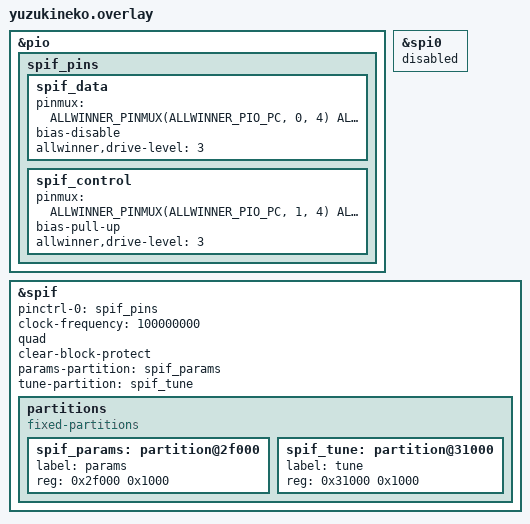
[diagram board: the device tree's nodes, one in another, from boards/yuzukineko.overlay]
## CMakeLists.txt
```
# Copyright (c) 2026 Yuzuki Tsuru
# SPDX-License-Identifier: Apache-2.0

cmake_minimum_required(VERSION 3.20.0)
find_package(Zephyr REQUIRED HINTS $ENV{ZEPHYR_BASE})
project(uf2_downloader)

target_sources(app PRIVATE src/main.c src/uf2.c src/msc.c)

# the flash is written from the MSC thread, not from the interrupt; one 4 KiB transfer at a time
zephyr_compile_definitions(CONFIG_USBDEV_MSC_THREAD=1 CONFIG_USBDEV_MSC_STACKSIZE=4096)
```

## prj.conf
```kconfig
CONFIG_CHERRYUSB=y
CONFIG_CHERRYUSB_DEVICE=y
CONFIG_CHERRYUSB_DEVICE_SPEED_HS=y
CONFIG_CHERRYUSB_DEVICE_MUSB_SUNXI=y
CONFIG_CHERRYUSB_DEVICE_MSC=y

CONFIG_FLASH=y
CONFIG_FLASH_PAGE_LAYOUT=y
CONFIG_CRC=y
CONFIG_ICACHE=y

CONFIG_PRINTK=y
CONFIG_LOG=n
CONFIG_SHELL=n
CONFIG_DEVMEM_SHELL=n
CONFIG_MAIN_STACK_SIZE=8192
CONFIG_SYSTEM_WORKQUEUE_STACK_SIZE=2048
CONFIG_HEAP_MEM_POOL_SIZE=65536

# nothing of the board is needed but the flash and the USB port
CONFIG_DISPLAY=n
CONFIG_G2D=n
CONFIG_VDEC=n
CONFIG_ADC=n
CONFIG_SPI=n
CONFIG_I2C=n
CONFIG_MIPI_DBI=n
CONFIG_WDT_SUNXI=n
CONFIG_REBOOT=y
CONFIG_USBDEV_MSC_MAX_BUFSIZE=4096
```

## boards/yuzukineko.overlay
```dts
/*
 * The SPI NOR flash (16 MiB) is on PC0..PC5, the pins of spi0.
 *
 *   0x000000  three copies of the boot loader (160 KiB)
 *   0x02f000  saved sample point of the flash controller
 *   0x030000  this program: header page, then the image (tune data = its first words)
 *   0x200000  applications (header page, then the image)
 */

#include <zephyr/dt-bindings/pinctrl/allwinner-pinctrl.h>

&pio {
	spif_pins: spif_pins {
		spif_data {
			pinmux = <ALLWINNER_PINMUX(ALLWINNER_PIO_PC, 0, 4)
				  ALLWINNER_PINMUX(ALLWINNER_PIO_PC, 4, 4)
				  ALLWINNER_PINMUX(ALLWINNER_PIO_PC, 2, 4)>;
			bias-disable;
			allwinner,drive-level = <3>;
		};
		spif_control {
			pinmux = <ALLWINNER_PINMUX(ALLWINNER_PIO_PC, 1, 4)
				  ALLWINNER_PINMUX(ALLWINNER_PIO_PC, 3, 4)
				  ALLWINNER_PINMUX(ALLWINNER_PIO_PC, 5, 4)>;
			bias-pull-up;
			allwinner,drive-level = <3>;
		};
	};
};

&spi0 {
	status = "disabled";
};

&spif {
	status = "okay";
	pinctrl-0 = <&spif_pins>;
	pinctrl-names = "default";
	clock-frequency = <100000000>;
	quad;
	clear-block-protect;
	params-partition = "spif_params";
	tune-partition = "spif_tune";

	partitions {
		compatible = "fixed-partitions";
		#address-cells = <1>;
		#size-cells = <1>;

		spif_params: partition@2f000 {
			label = "params";
			reg = <0x2f000 0x1000>;
		};
		spif_tune: partition@31000 {
			label = "tune";
			reg = <0x31000 0x1000>;
		};
	};
};
```

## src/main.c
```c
/*
 * Copyright (c) 2026 Yuzuki Tsuru
 * SPDX-License-Identifier: Apache-2.0
 */

/*
 * UF2 boot mode: the board shows up as a USB drive, a .uf2 file copied onto it is written
 * to the SPI NOR flash, and the board restarts into the application when the file is done.
 * The boot loader starts this program when the key is held or no application is in the flash.
 */

#include <zephyr/device.h>
#include <zephyr/drivers/gpio.h>
#include <zephyr/kernel.h>
#include <zephyr/sys/printk.h>
#include <zephyr/sys/reboot.h>

#include "usbd_core.h"
#include "usbd_msc.h"

#include "uf2.h"

extern uintptr_t usb_sunxi_otg_base(void);

#define MSC_IN_EP  0x81
#define MSC_OUT_EP 0x02

#define USBD_VID	   0x1209
#define USBD_PID	   0xF101
#define USBD_MAX_POWER	   100
#define USB_CONFIG_SIZE	   (9 + MSC_DESCRIPTOR_LEN)

static const uint8_t device_descriptor[] = {
	USB_DEVICE_DESCRIPTOR_INIT(USB_2_0, 0x00, 0x00, 0x00, USBD_VID, USBD_PID, 0x0200, 0x01)
};

static const uint8_t config_hs[] = {
	USB_CONFIG_DESCRIPTOR_INIT(USB_CONFIG_SIZE, 0x01, 0x01, USB_CONFIG_BUS_POWERED,
				   USBD_MAX_POWER),
	MSC_DESCRIPTOR_INIT(0x00, MSC_OUT_EP, MSC_IN_EP, USB_BULK_EP_MPS_HS, 0x02)
};

static const uint8_t config_fs[] = {
	USB_CONFIG_DESCRIPTOR_INIT(USB_CONFIG_SIZE, 0x01, 0x01, USB_CONFIG_BUS_POWERED,
				   USBD_MAX_POWER),
	MSC_DESCRIPTOR_INIT(0x00, MSC_OUT_EP, MSC_IN_EP, USB_BULK_EP_MPS_FS, 0x02)
};

static const uint8_t qualifier[] = {USB_DEVICE_QUALIFIER_DESCRIPTOR_INIT(USB_2_0, 0x00, 0x00, 0x00, 0x01)};

static const uint8_t other_hs[] = {
	USB_OTHER_SPEED_CONFIG_DESCRIPTOR_INIT(USB_CONFIG_SIZE, 0x01, 0x01, USB_CONFIG_BUS_POWERED,
					       USBD_MAX_POWER),
	MSC_DESCRIPTOR_INIT(0x00, MSC_OUT_EP, MSC_IN_EP, USB_BULK_EP_MPS_FS, 0x02)
};

static const uint8_t other_fs[] = {
	USB_OTHER_SPEED_CONFIG_DESCRIPTOR_INIT(USB_CONFIG_SIZE, 0x01, 0x01, USB_CONFIG_BUS_POWERED,
					       USBD_MAX_POWER),
	MSC_DESCRIPTOR_INIT(0x00, MSC_OUT_EP, MSC_IN_EP, USB_BULK_EP_MPS_HS, 0x02)
};

static const char *strings[] = {
	(const char[]){0x09, 0x04},
	"Yuzuki",
	"F101 UF2 Bootloader",
	"F101BOOT0001",
};

static const uint8_t *device_cb(uint8_t speed)
{
	return device_descriptor;
}

static const uint8_t *config_cb(uint8_t speed)
{
	return speed == USB_SPEED_HIGH ? config_hs : speed == USB_SPEED_FULL ? config_fs : NULL;
}

static const uint8_t *qualifier_cb(uint8_t speed)
{
	return qualifier;
}

static const uint8_t *other_cb(uint8_t speed)
{
	return speed == USB_SPEED_HIGH ? other_hs : speed == USB_SPEED_FULL ? other_fs : NULL;
}

static const char *string_cb(uint8_t speed, uint8_t index)
{
	return index < ARRAY_SIZE(strings) ? strings[index] : NULL;
}

static const struct usb_descriptor descriptor = {
	.device_descriptor_callback = device_cb,
	.config_descriptor_callback = config_cb,
	.device_quality_descriptor_callback = qualifier_cb,
	.other_speed_descriptor_callback = other_cb,
	.string_descriptor_callback = string_cb,
};

static struct usbd_interface intf0;

static void event_handler(uint8_t busid, uint8_t event)
{
	if (event == USBD_EVENT_CONFIGURED) {
		printk("uf2-downloader: USB configured\n");
	}
}

int main(void)
{
	int ret = uf2_init();

	if (ret != 0) {
		printk("[E] uf2-downloader: flash not usable: %d\n", ret);
		return 0;
	}
	usbd_desc_register(0, &descriptor);
	usbd_add_interface(0, usbd_msc_init_intf(0, &intf0, MSC_OUT_EP, MSC_IN_EP));
	usbd_initialize(0, usb_sunxi_otg_base(), event_handler);
	printk("uf2-downloader: ready, copy a .uf2 file onto the F101BOOT drive\n");

	uint32_t last = 0;
	int quiet = 0, key = -1;
	const struct device *gpio = DEVICE_DT_GET(DT_NODELABEL(gpiod));

	gpio_pin_configure(gpio, 5, GPIO_INPUT | GPIO_PULL_UP);

	while (true) {
		k_msleep(20);
		int level = gpio_pin_get_raw(gpio, 5);

		if (level != key) {
			key = level;
			printk("uf2-downloader: key (PD5) = %d\n", key);
		}
		if (uf2_complete()) {
			/* the host still writes its file system tables */
			k_msleep(1000);
			printk("uf2-downloader: done, restarting\n");
			sys_reboot(SYS_REBOOT_COLD);
		}
		if (uf2_blocks_done() != last) {
			last = uf2_blocks_done();
			quiet = 0;
		} else if (++quiet == 250 && last != 0U) {
			printk("uf2-downloader: %u of %u blocks, %u errors\n", last, uf2_blocks_total(),
			       uf2_errors());
		}
	}
	return 0;
}
```

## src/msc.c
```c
/*
 * Copyright (c) 2026 Yuzuki Tsuru
 * SPDX-License-Identifier: Apache-2.0
 */

/*
 * A FAT16 volume that exists only as the code below: the boot sector, the tables, the root
 * directory and two small files are made when read, everything written is looked at for
 * UF2 blocks and dropped otherwise. 128 MiB, so a big UF2 file is not refused for space.
 */

#include <string.h>

#include "usbd_core.h"
#include "usbd_msc.h"

#include "uf2.h"

#define SECTOR_SIZE	512U
#define NUM_SECTORS	262144U
#define SEC_PER_CLUSTER 8U
#define FAT_SECTORS	128U /* 32768 clusters * 2 bytes */
#define ROOT_ENTRIES	512U
#define ROOT_SECTORS	(ROOT_ENTRIES * 32U / SECTOR_SIZE)
#define FAT1_START	1U
#define FAT2_START	(FAT1_START + FAT_SECTORS)
#define ROOT_START	(FAT2_START + FAT_SECTORS)
#define DATA_START	(ROOT_START + ROOT_SECTORS)

static const char info_txt[] =
	"UF2 Bootloader for the Allwinner F101\r\n"
	"Model: YuzukiNeko\r\n"
	"Board-ID: F101-Neko\r\n"
	"Flash: applications from 0x200000, family 0x31303146\r\n";

static const char index_htm[] =
	"<!doctype html><html><body><script>location.replace(\"https://github.com/YuzukiHD\");"
	"</script></body></html>\r\n";

struct vfile {
	const char name[11];
	const char *data;
	uint16_t size;
};

static const struct vfile files[] = {
	{"INFO_UF2TXT", info_txt, sizeof(info_txt) - 1},
	{"INDEX   HTM", index_htm, sizeof(index_htm) - 1},
};

#define FIRST_FILE_CLUSTER 2U

static void put16(uint8_t *p, uint16_t v)
{
	p[0] = v;
	p[1] = v >> 8;
}

static void put32(uint8_t *p, uint32_t v)
{
	put16(p, v);
	put16(p + 2, v >> 16);
}

static void boot_sector(uint8_t *b)
{
	memset(b, 0, SECTOR_SIZE);
	b[0] = 0xEB;
	b[1] = 0x3C;
	b[2] = 0x90;
	memcpy(b + 3, "UF2 UF2 ", 8);
	put16(b + 11, SECTOR_SIZE);
	b[13] = SEC_PER_CLUSTER;
	put16(b + 14, 1);
	b[16] = 2;
	put16(b + 17, ROOT_ENTRIES);
	put16(b + 19, 0);
	b[21] = 0xF8;
	put16(b + 22, FAT_SECTORS);
	put16(b + 24, 63);
	put16(b + 26, 255);
	put32(b + 28, 0);
	put32(b + 32, NUM_SECTORS);
	b[36] = 0x80;
	b[38] = 0x29;
	put32(b + 39, 0x00420042);
	memcpy(b + 43, "F101BOOT   ", 11);
	memcpy(b + 54, "FAT16   ", 8);
	b[510] = 0x55;
	b[511] = 0xAA;
}

static uint16_t fat_entry(uint32_t idx)
{
	if (idx == 0) {
		return 0xFFF8;
	}
	if (idx == 1) {
		return 0xFFFF;
	}
	if (idx >= FIRST_FILE_CLUSTER && idx < FIRST_FILE_CLUSTER + ARRAY_SIZE(files)) {
		return 0xFFFF; /* every file is one cluster */
	}
	return 0;
}

static void root_sector(uint32_t n, uint8_t *b)
{
	memset(b, 0, SECTOR_SIZE);
	if (n != 0U) {
		return;
	}
	/* volume label, then the files; 1 Jan 2026 */
	memcpy(b, "F101BOOT   ", 11);
	b[11] = 0x08;
	for (unsigned int i = 0; i < ARRAY_SIZE(files); i++) {
		uint8_t *e = b + 32 * (i + 1);

		memcpy(e, files[i].name, 11);
		e[11] = 0x01; /* read only */
		put16(e + 14, 0);
		put16(e + 16, ((2026 - 1980) << 9) | (1 << 5) | 1);
		put16(e + 24, ((2026 - 1980) << 9) | (1 << 5) | 1);
		put16(e + 26, FIRST_FILE_CLUSTER + i);
		put32(e + 28, files[i].size);
	}
}

static void read_sector(uint32_t s, uint8_t *b)
{
	if (s == 0U) {
		boot_sector(b);
	} else if (s < ROOT_START) {
		uint32_t n = (s - FAT1_START) % FAT_SECTORS;

		for (unsigned int i = 0; i < SECTOR_SIZE / 2U; i++) {
			put16(b + 2U * i, fat_entry(n * (SECTOR_SIZE / 2U) + i));
		}
	} else if (s < DATA_START) {
		root_sector(s - ROOT_START, b);
	} else {
		uint32_t cluster = FIRST_FILE_CLUSTER + (s - DATA_START) / SEC_PER_CLUSTER;
		uint32_t in_cluster = (s - DATA_START) % SEC_PER_CLUSTER;

		memset(b, 0, SECTOR_SIZE);
		if (cluster < FIRST_FILE_CLUSTER + ARRAY_SIZE(files) && in_cluster == 0U) {
			const struct vfile *f = &files[cluster - FIRST_FILE_CLUSTER];

			memcpy(b, f->data, f->size);
		}
	}
}

void usbd_msc_get_cap(uint8_t busid, uint8_t lun, uint32_t *block_num, uint32_t *block_size)
{
	*block_num = NUM_SECTORS;
	*block_size = SECTOR_SIZE;
}

int usbd_msc_sector_read(uint8_t busid, uint8_t lun, uint32_t sector, uint8_t *buffer,
			 uint32_t length)
{
	for (uint32_t i = 0; i < length / SECTOR_SIZE; i++) {
		read_sector(sector + i, buffer + i * SECTOR_SIZE);
	}
	return 0;
}

int usbd_msc_sector_write(uint8_t busid, uint8_t lun, uint32_t sector, uint8_t *buffer,
			  uint32_t length)
{
	for (uint32_t i = 0; i < length / SECTOR_SIZE; i++) {
		(void)uf2_write_block(buffer + i * SECTOR_SIZE);
	}
	return 0;
}
```

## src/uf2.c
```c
/*
 * Copyright (c) 2026 Yuzuki Tsuru
 * SPDX-License-Identifier: Apache-2.0
 */

/* UF2 blocks -> SPI NOR flash */

#include <string.h>

#include <zephyr/device.h>
#include <zephyr/drivers/flash.h>
#include <zephyr/kernel.h>
#include <zephyr/sys/printk.h>

#include "uf2.h"

#define SECTOR 4096U

static const struct device *const flash = DEVICE_DT_GET(DT_NODELABEL(spif));
static uint32_t flash_size;
/* 4 KiB sectors erased for the file in progress */
static uint8_t erased[4096 / 8];
static uint32_t done, total, errors;
static bool complete;
static uint32_t file_family;

int uf2_init(void)
{
	uint64_t size;

	if (!device_is_ready(flash)) {
		return -ENODEV;
	}
	if (flash_get_size(flash, &size) != 0 || size == 0U) {
		return -EIO;
	}
	flash_size = size;
	return 0;
}

static bool allowed(uint32_t family, uint32_t addr, uint32_t len)
{
	if (len == 0U || addr + len < addr || addr + len > flash_size) {
		return false;
	}
	if (family == UF2_FAMILY_APP) {
		return addr >= UF2_APP_BASE;
	}
	return family == UF2_FAMILY_SYS;
}

static int prepare(uint32_t addr, uint32_t len)
{
	for (uint32_t s = addr / SECTOR; s <= (addr + len - 1U) / SECTOR; s++) {
		if (erased[s / 8U] & BIT(s % 8U)) {
			continue;
		}
		int ret = flash_erase(flash, s * SECTOR, SECTOR);

		if (ret != 0) {
			return ret;
		}
		erased[s / 8U] |= BIT(s % 8U);
	}
	return 0;
}

bool uf2_write_block(const uint8_t *buf)
{
	const struct uf2_block *b = (const struct uf2_block *)buf;

	if (b->magic0 != UF2_MAGIC_START0 || b->magic1 != UF2_MAGIC_START1 ||
	    b->magic_end != UF2_MAGIC_END) {
		return false;
	}
	if ((b->flags & UF2_FLAG_NOT_MAIN_FLASH) != 0U) {
		return true;
	}
	if ((b->flags & UF2_FLAG_FAMILY_ID) == 0U || b->payload_size > sizeof(b->data) ||
	    !allowed(b->family, b->target_addr, b->payload_size)) {
		errors++;
		printk("uf2: block %u refused (family 0x%08x, address 0x%08x, %u bytes)\n",
		       b->block_no, b->family, b->target_addr, b->payload_size);
		return true;
	}
	if (b->block_no == 0U || b->family != file_family || b->num_blocks != total) {
		/* the first block of a new file */
		memset(erased, 0, sizeof(erased));
		done = 0;
		errors = 0;
		complete = false;
		total = b->num_blocks;
		file_family = b->family;
		printk("uf2: new file, %u blocks, family 0x%08x\n", total, file_family);
	}
	if (prepare(b->target_addr, b->payload_size) != 0 ||
	    flash_write(flash, b->target_addr, b->data, b->payload_size) != 0) {
		errors++;
		printk("uf2: flash error at 0x%08x\n", b->target_addr);
		return true;
	}
	if (++done >= total && errors == 0U) {
		complete = true;
		printk("uf2: %u blocks written\n", done);
	}
	return true;
}

uint32_t uf2_blocks_done(void)
{
	return done;
}

uint32_t uf2_blocks_total(void)
{
	return total;
}

uint32_t uf2_errors(void)
{
	return errors;
}

bool uf2_complete(void)
{
	return complete;
}
```

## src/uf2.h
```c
/* SPDX-License-Identifier: Apache-2.0 */
#pragma once

#include <stdbool.h>
#include <stdint.h>

#define UF2_MAGIC_START0 0x0A324655U /* "UF2\n" */
#define UF2_MAGIC_START1 0x9E5D5157U
#define UF2_MAGIC_END	 0x0AB16F30U

#define UF2_FLAG_NOT_MAIN_FLASH 0x00000001U
#define UF2_FLAG_FAMILY_ID	0x00002000U

/* applications: flash offsets from APP_BASE on */
#define UF2_FAMILY_APP 0x31303146U
/* everything (loader, this program): the same file format, offsets from 0 */
#define UF2_FAMILY_SYS 0x31303147U

#define UF2_APP_BASE 0x00200000U

struct uf2_block {
	uint32_t magic0, magic1;
	uint32_t flags;
	uint32_t target_addr;
	uint32_t payload_size;
	uint32_t block_no;
	uint32_t num_blocks;
	uint32_t family;
	uint8_t data[476];
	uint32_t magic_end;
};

/** Initialise; returns 0 or a negative errno when the flash is not usable. */
int uf2_init(void);

/**
 * Handle a 512 byte block written to the volume. Returns false when it is not a UF2 block
 * (a file system write), true when it was one, whatever came of it.
 */
bool uf2_write_block(const uint8_t *buf);

/** The state for the console: blocks written, blocks of the file, errors. */
uint32_t uf2_blocks_done(void);
uint32_t uf2_blocks_total(void);
uint32_t uf2_errors(void);

/** Set once every block of a file has been written. */
bool uf2_complete(void);
```
